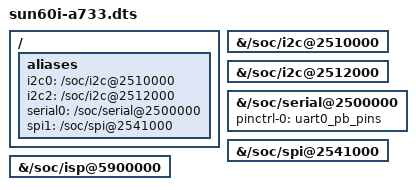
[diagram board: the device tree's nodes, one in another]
// Generated by `lemnos-ctl tree` from board "sun60i-a733". Do not edit: change the
// board file or the SoC map, and generate again.
// Every fragment says why it is here. Node paths are the base tree's.
// i2c: an I2C (TWI) controller on the A733 (allwinner,sun60i-a733-i2c) (alias i2c0, the name "i2c-0")
&{/soc/i2c@2510000} {
	status = "okay";
};
// the runtime name comes out of alias i2c0
/ {
	aliases { i2c0 = "/soc/i2c@2510000"; };
};
// i2c: an I2C (TWI) controller on the A733 (allwinner,sun60i-a733-i2c) (alias i2c2, the name "i2c-2")
&{/soc/i2c@2512000} {
	status = "okay";
};
// the runtime name comes out of alias i2c2
/ {
	aliases { i2c2 = "/soc/i2c@2512000"; };
};
// uart: a serial port on the A733 (snps,dw-apb-uart) (alias serial0) on GPIO41, GPIO42
&{/soc/serial@2500000} {
	status = "okay";
	pinctrl-names = "default";
	pinctrl-0 = <&uart0_pb_pins>;
};
// the runtime name comes out of alias serial0
/ {
	aliases { serial0 = "/soc/serial@2500000"; };
};
// spi: an SPI controller on the A733 (allwinner,sun60i-a733-spi-dbi) (alias spi1, the name "spidev1.0")
&{/soc/spi@2541000} {
	status = "okay";
};
// the runtime name comes out of alias spi1
/ {
	aliases { spi1 = "/soc/spi@2541000"; };
};
// block: the image signal processor on the A733 (allwinner,sun60i-a733-isp)
&{/soc/isp@5900000} {
	status = "okay";
};
